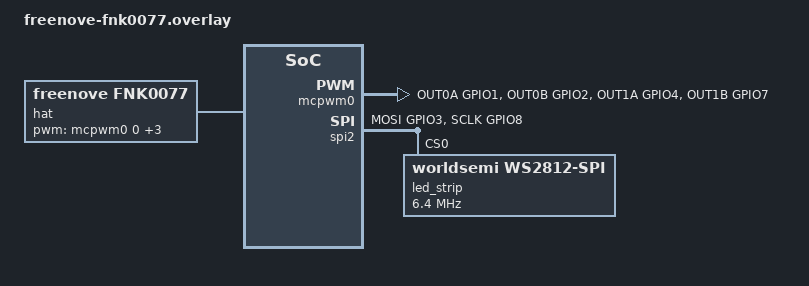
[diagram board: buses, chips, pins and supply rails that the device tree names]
#include <zephyr/dt-bindings/pinctrl/esp32s3-pinctrl.h>
#include <zephyr/dt-bindings/pwm/pwm.h>
#include <zephyr/dt-bindings/led/led.h>

 /* XIAO     HAT (PIN, not GPIO) */
 /*  D0  --> 18  left motor  fwd */
 /*  D1  --> 16  left motor  bwd */
 /*  D3  --> 29  right motor fwd */
 /*  D8  --> 31  right motor bwd */
 /*  D2  --> 19  WS2812 data */
 /*  5V  --> 2   power (needs S1 on) */
 /*  GND --> 6 */

&pinctrl {
	mcpwm0_hat: mcpwm0_hat {
		group1 {
			pinmux = <MCPWM0_OUT0A_GPIO1>, <MCPWM0_OUT0B_GPIO2>,
				 <MCPWM0_OUT1A_GPIO4>, <MCPWM0_OUT1B_GPIO7>;
			output-enable;
		};
	};

	spim2_ws2812: spim2_ws2812 {
		group1 {
			pinmux = <SPIM2_MOSI_GPIO3>, <SPIM2_SCLK_GPIO8>;
			output-low;
		};
	};
};

&mcpwm0 {
	pinctrl-0 = <&mcpwm0_hat>;
	pinctrl-names = "default";
	prescale = <15>;
	prescale-timer0 = <0>;
	prescale-timer1 = <0>;
	status = "okay";
};

&spi2 {
	status = "okay";
	pinctrl-0 = <&spim2_ws2812>;
	pinctrl-names = "default";
	#address-cells = <1>;
	#size-cells = <0>;

	led_strip: ws2812@0 {
		compatible = "worldsemi,ws2812-spi";
		reg = <0>;
		spi-max-frequency = <6400000>;
		chain-length = <4>;
		spi-one-frame = <0xF8>;
		spi-zero-frame = <0x80>;
		color-mapping = <LED_COLOR_ID_GREEN>,
				<LED_COLOR_ID_RED>,
				<LED_COLOR_ID_BLUE>;
	};
};

/ {
	hat {
		compatible = "freenove,fnk0077";
		pwms = <&mcpwm0 0 PWM_MSEC(1) PWM_POLARITY_NORMAL>,
		       <&mcpwm0 1 PWM_MSEC(1) PWM_POLARITY_NORMAL>,
		       <&mcpwm0 2 PWM_MSEC(1) PWM_POLARITY_NORMAL>,
		       <&mcpwm0 3 PWM_MSEC(1) PWM_POLARITY_NORMAL>;
		pwm-names = "left-forward", "left-backward", "right-forward", "right-backward";
	};
};
